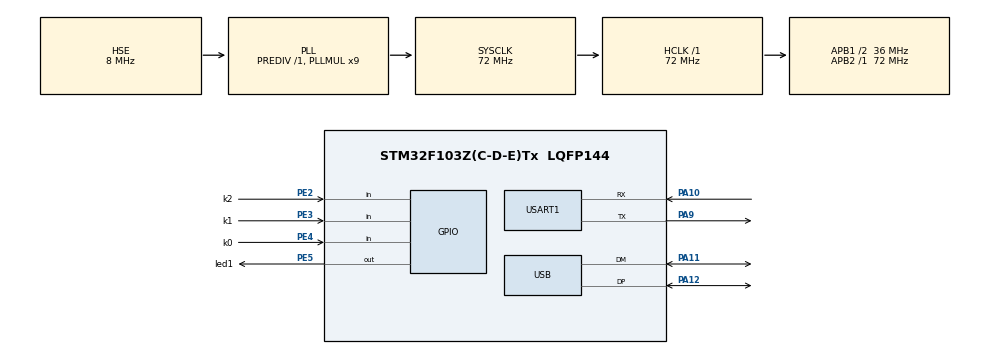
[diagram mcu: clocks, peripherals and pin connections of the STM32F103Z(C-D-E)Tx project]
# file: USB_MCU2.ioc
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Mcu.Family=STM32F1
Mcu.Name=STM32F103Z(C-D-E)Tx
Mcu.Package=LQFP144
NVIC.PriorityGroup=NVIC_PRIORITYGROUP_4
NVIC.USB_LP_CAN1_RX0_IRQn=true\:0\:0\:false\:false\:true\:false
OSC_IN.Mode=HSE-External-Oscillator
OSC_IN.Signal=RCC_OSC_IN
OSC_OUT.Mode=HSE-External-Oscillator
OSC_OUT.Signal=RCC_OSC_OUT
PA10.Mode=Asynchronous
PA10.Signal=USART1_RX
PA11.Mode=Device
PA11.Signal=USB_DM
PA12.Mode=Device
PA12.Signal=USB_DP
PA9.Mode=Asynchronous
PA9.Signal=USART1_TX
PC14-OSC32_IN.Mode=LSE-External-Oscillator
PC14-OSC32_IN.Signal=RCC_OSC32_IN
PC15-OSC32_OUT.Mode=LSE-External-Oscillator
PC15-OSC32_OUT.Signal=RCC_OSC32_OUT
PE2.GPIO_Label=k2
PE2.GPIO_PuPd=GPIO_PULLUP
PE2.Signal=GPIO_Input
PE3.GPIO_Label=k1
PE3.GPIO_PuPd=GPIO_PULLUP
PE3.Signal=GPIO_Input
PE4.GPIO_Label=k0
PE4.GPIO_PuPd=GPIO_PULLUP
PE4.Signal=GPIO_Input
PE5.GPIO_Label=led1
PE5.GPIO_PuPd=GPIO_PULLUP
PE5.PinState=GPIO_PIN_SET
PE5.Signal=GPIO_Output
ProjectManager.HeapSize=0x200
ProjectManager.StackSize=0x400
ProjectManager.TargetToolchain=MDK-ARM V5
RCC.AHBFreq_Value=72000000
RCC.APB1CLKDivider=RCC_HCLK_DIV2
RCC.APB1Freq_Value=36000000
RCC.APB1TimFreq_Value=72000000
RCC.APB2Freq_Value=72000000
RCC.APB2TimFreq_Value=72000000
RCC.HCLKFreq_Value=72000000
RCC.PLLMUL=RCC_PLL_MUL9
RCC.SYSCLKFreq_VALUE=72000000
RCC.SYSCLKSource=RCC_SYSCLKSOURCE_PLLCLK
RCC.USBFreq_Value=48000000
RCC.USBPrescaler=RCC_USBCLKSOURCE_PLL_DIV1_5
USART1.VirtualMode=VM_ASYNC
USB_DEVICE.CLASS_NAME_FS=CUSTOMHID
USB_DEVICE.PID_CUSTOMHID_FS=0x82cd
USB_DEVICE.USBD_CUSTOMHID_OUTREPORT_BUF_SIZE=64
USB_DEVICE.USBD_CUSTOM_HID_REPORT_DESC_SIZE=34
USB_DEVICE.VID=0x10c4
USB_DEVICE.VirtualMode=CustomHid
USB_DEVICE.VirtualModeFS=Custom_Hid_FS
VP_SYS_VS_ND.Mode=No_Debug
VP_USB_DEVICE_VS_USB_DEVICE_CUSTOM_HID_FS.Mode=CUSTOM_HID_FS
board=custom

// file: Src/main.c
/**
  ******************************************************************************
  * @file           : main.c
  * @brief          : Main program body
  ******************************************************************************
  * This notice applies to any and all portions of this file
  * that are not between comment pairs USER CODE BEGIN and
  * USER CODE END. Other portions of this file, whether
  * inserted by the user or by software development tools
  * are owned by their respective copyright owners.
  *
  * Copyright (c) 2018 STMicroelectronics International N.V.
  * All rights reserved.
  *
  * Redistribution and use in source and binary forms, with or without
  * modification, are permitted, provided that the following conditions are met:
  *
  * 1. Redistribution of source code must retain the above copyright notice,
  *    this list of conditions and the following disclaimer.
  * 2. Redistributions in binary form must reproduce the above copyright notice,
  *    this list of conditions and the following disclaimer in the documentation
  *    and/or other materials provided with the distribution.
  * 3. Neither the name of STMicroelectronics nor the names of other
  *    contributors to this software may be used to endorse or promote products
  *    derived from this software without specific written permission.
  * 4. This software, including modifications and/or derivative works of this
  *    software, must execute solely and exclusively on microcontroller or
  *    microprocessor devices manufactured by or for STMicroelectronics.
  * 5. Redistribution and use of this software other than as permitted under
  *    this license is void and will automatically terminate your rights under
  *    this license.
  *
  * THIS SOFTWARE IS PROVIDED BY STMICROELECTRONICS AND CONTRIBUTORS "AS IS"
  * AND ANY EXPRESS, IMPLIED OR STATUTORY WARRANTIES, INCLUDING, BUT NOT
  * LIMITED TO, THE IMPLIED WARRANTIES OF MERCHANTABILITY, FITNESS FOR A
  * PARTICULAR PURPOSE AND NON-INFRINGEMENT OF THIRD PARTY INTELLECTUAL PROPERTY
  * RIGHTS ARE DISCLAIMED TO THE FULLEST EXTENT PERMITTED BY LAW. IN NO EVENT
  * SHALL STMICROELECTRONICS OR CONTRIBUTORS BE LIABLE FOR ANY DIRECT, INDIRECT,
  * INCIDENTAL, SPECIAL, EXEMPLARY, OR CONSEQUENTIAL DAMAGES (INCLUDING, BUT NOT
  * LIMITED TO, PROCUREMENT OF SUBSTITUTE GOODS OR SERVICES; LOSS OF USE, DATA,
  * OR PROFITS; OR BUSINESS INTERRUPTION) HOWEVER CAUSED AND ON ANY THEORY OF
  * LIABILITY, WHETHER IN CONTRACT, STRICT LIABILITY, OR TORT (INCLUDING
  * NEGLIGENCE OR OTHERWISE) ARISING IN ANY WAY OUT OF THE USE OF THIS SOFTWARE,
  * EVEN IF ADVISED OF THE POSSIBILITY OF SUCH DAMAGE.
  *
  ******************************************************************************
  */
#include "main.h"
#include "stm32f1xx_hal.h"
#include "usb_device.h"

UART_HandleTypeDef huart1;

/* USER CODE BEGIN PV */
/* Private variables ---------------------------------------------------------*/

/* USER CODE END PV */

void SystemClock_Config(void);
static void MX_GPIO_Init(void);
static void MX_USART1_UART_Init(void);

/* USER CODE BEGIN PFP */
/* Private function prototypes -----------------------------------------------*/

/* USER CODE END PFP */

/* USER CODE BEGIN 0 */
#include "usbd_customhid.h" //包括发送函数头文件
unsigned char USB_Recive_Buffer[64]; //USB接收缓存
unsigned char USB_Received_Count = 0;//USB接收数据计数
extern USBD_HandleTypeDef hUsbDeviceFS; //外部声明USB发送函数
/* USER CODE END 0 */

int main(void)
{
  /* USER CODE BEGIN 1 */
	uint8_t send_buf[64] = {//定义一个USB的发送BUFF
													1,2,3,4,5,6,7,8,9,10,11,12,13,14,15,16,
													17,18,19,20,21,22,23,24,25,26,27,28,29,30,31,32,33,34,35,36,37,38,39,
													40,41,42,43,44,45,46,47,48,49,50,51,52,53,54,55,56,57,58,59,60,61,62,63,64};

  /* USER CODE END 1 */

  /* MCU Configuration----------------------------------------------------------*/

  /* Reset of all peripherals, Initializes the Flash interface and the Systick. */
  HAL_Init();

  /* Configure the system clock */
  SystemClock_Config();

  /* Initialize all configured peripherals */
  MX_GPIO_Init();
  MX_USB_DEVICE_Init();
  MX_USART1_UART_Init();

  /* Infinite loop */
  while (1)
  {

  /* USER CODE BEGIN 3 */
		if(HAL_GPIO_ReadPin(GPIOE,k1_Pin)==0||HAL_GPIO_ReadPin(GPIOE,k2_Pin)==0||HAL_GPIO_ReadPin(GPIOE,k0_Pin)==0)
		{
			//按键消抖
			while(HAL_GPIO_ReadPin(GPIOE,k1_Pin)==0||HAL_GPIO_ReadPin(GPIOE,k2_Pin)==0||HAL_GPIO_ReadPin(GPIOE,k0_Pin)==0);
			//点亮指示灯
			HAL_GPIO_WritePin(GPIOE,led1_Pin,GPIO_PIN_RESET);
			//USB发送数据
			USBD_CUSTOM_HID_SendReport(&hUsbDeviceFS, send_buf, sizeof(send_buf)); //实际发送到上位机的数据有65个，一个报文ID+64个send_buf数据，一共65个数据到上位机
			HAL_Delay(1000);
			//关闭指示灯
			HAL_GPIO_WritePin(GPIOE,led1_Pin,GPIO_PIN_SET);

		}
  }
  /* USER CODE END 3 */

}

void SystemClock_Config(void)
{

  RCC_OscInitTypeDef RCC_OscInitStruct;
  RCC_ClkInitTypeDef RCC_ClkInitStruct;
  RCC_PeriphCLKInitTypeDef PeriphClkInit;

    /**Initializes the CPU, AHB and APB busses clocks
    */
  RCC_OscInitStruct.OscillatorType = RCC_OSCILLATORTYPE_HSE;
  RCC_OscInitStruct.HSEState = RCC_HSE_ON;
  RCC_OscInitStruct.HSEPredivValue = RCC_HSE_PREDIV_DIV1;
  RCC_OscInitStruct.HSIState = RCC_HSI_ON;
  RCC_OscInitStruct.PLL.PLLState = RCC_PLL_ON;
  RCC_OscInitStruct.PLL.PLLSource = RCC_PLLSOURCE_HSE;
  RCC_OscInitStruct.PLL.PLLMUL = RCC_PLL_MUL9;
  if (HAL_RCC_OscConfig(&RCC_OscInitStruct) != HAL_OK)
  {
    _Error_Handler(__FILE__, __LINE__);
  }

    /**Initializes the CPU, AHB and APB busses clocks
    */
  RCC_ClkInitStruct.ClockType = RCC_CLOCKTYPE_HCLK|RCC_CLOCKTYPE_SYSCLK
                              |RCC_CLOCKTYPE_PCLK1|RCC_CLOCKTYPE_PCLK2;
  RCC_ClkInitStruct.SYSCLKSource = RCC_SYSCLKSOURCE_PLLCLK;
  RCC_ClkInitStruct.AHBCLKDivider = RCC_SYSCLK_DIV1;
  RCC_ClkInitStruct.APB1CLKDivider = RCC_HCLK_DIV2;
  RCC_ClkInitStruct.APB2CLKDivider = RCC_HCLK_DIV1;

  if (HAL_RCC_ClockConfig(&RCC_ClkInitStruct, FLASH_LATENCY_2) != HAL_OK)
  {
    _Error_Handler(__FILE__, __LINE__);
  }

  PeriphClkInit.PeriphClockSelection = RCC_PERIPHCLK_USB;
  PeriphClkInit.UsbClockSelection = RCC_USBCLKSOURCE_PLL_DIV1_5;
  if (HAL_RCCEx_PeriphCLKConfig(&PeriphClkInit) != HAL_OK)
  {
    _Error_Handler(__FILE__, __LINE__);
  }

    /**Configure the Systick interrupt time
    */
  HAL_SYSTICK_Config(HAL_RCC_GetHCLKFreq()/1000);

    /**Configure the Systick
    */
  HAL_SYSTICK_CLKSourceConfig(SYSTICK_CLKSOURCE_HCLK);

  /* SysTick_IRQn interrupt configuration */
  HAL_NVIC_SetPriority(SysTick_IRQn, 0, 0);
}

/* USART1 init function */
static void MX_USART1_UART_Init(void)
{

  huart1.Instance = USART1;
  huart1.Init.BaudRate = 115200;
  huart1.Init.WordLength = UART_WORDLENGTH_8B;
  huart1.Init.StopBits = UART_STOPBITS_1;
  huart1.Init.Parity = UART_PARITY_NONE;
  huart1.Init.Mode = UART_MODE_TX_RX;
  huart1.Init.HwFlowCtl = UART_HWCONTROL_NONE;
  huart1.Init.OverSampling = UART_OVERSAMPLING_16;
  if (HAL_UART_Init(&huart1) != HAL_OK)
  {
    _Error_Handler(__FILE__, __LINE__);
  }

}

/** Configure pins as
        * Analog
        * Input
        * Output
        * EVENT_OUT
        * EXTI
*/
static void MX_GPIO_Init(void)
{

  GPIO_InitTypeDef GPIO_InitStruct;

  /* GPIO Ports Clock Enable */
  __HAL_RCC_GPIOE_CLK_ENABLE();
  __HAL_RCC_GPIOC_CLK_ENABLE();
  __HAL_RCC_GPIOA_CLK_ENABLE();

  /*Configure GPIO pin Output Level */
  HAL_GPIO_WritePin(led1_GPIO_Port, led1_Pin, GPIO_PIN_SET);

  /*Configure GPIO pins : k2_Pin k1_Pin k0_Pin */
  GPIO_InitStruct.Pin = k2_Pin|k1_Pin|k0_Pin;
  GPIO_InitStruct.Mode = GPIO_MODE_INPUT;
  GPIO_InitStruct.Pull = GPIO_PULLUP;
  HAL_GPIO_Init(GPIOE, &GPIO_InitStruct);

  /*Configure GPIO pin : led1_Pin */
  GPIO_InitStruct.Pin = led1_Pin;
  GPIO_InitStruct.Mode = GPIO_MODE_OUTPUT_PP;
  GPIO_InitStruct.Pull = GPIO_PULLUP;
  GPIO_InitStruct.Speed = GPIO_SPEED_FREQ_LOW;
  HAL_GPIO_Init(led1_GPIO_Port, &GPIO_InitStruct);

}

void _Error_Handler(char *file, int line)
{
  while(1)
  {
  }
}

/************************ (C) COPYRIGHT STMicroelectronics *****END OF FILE****/
